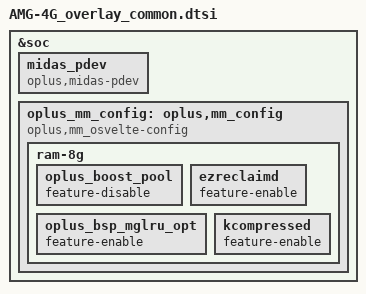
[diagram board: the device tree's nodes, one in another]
#include "fingerprint/uff_sm6225_AMG-4G.dtsi"
#include "oplus_thermal/oplus_thermal.dtsi"
#include "tp/AMG-4G_touchpanel.dtsi"

&soc {
	midas_pdev {
		compatible = "oplus,midas-pdev";
	};
};

&soc {
	oplus_mm_config: oplus,mm_config {
		compatible = "oplus,mm_osvelte-config";
		ram-8g {
			oplus_boost_pool {
				feature-disable;
			};
			ezreclaimd {
				feature-enable;
			};
			oplus_bsp_mglru_opt {
				feature-enable;
			};
			kcompressed {
				feature-enable;
			};
		};
	};
};

